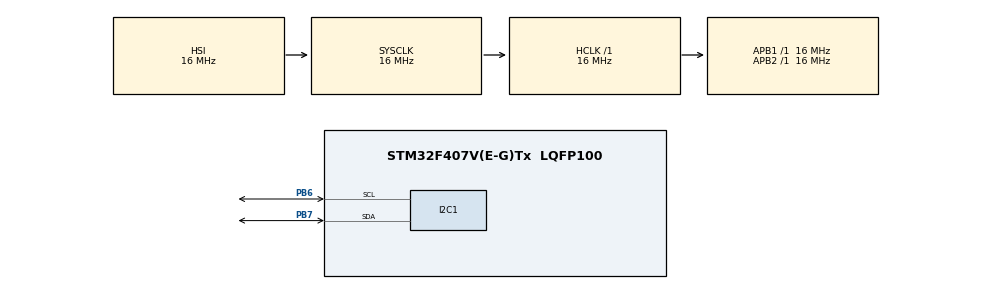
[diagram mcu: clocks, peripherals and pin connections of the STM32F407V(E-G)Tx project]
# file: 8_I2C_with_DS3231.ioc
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I2C1.I2C_Mode=I2C_Fast
Mcu.Family=STM32F4
Mcu.Name=STM32F407V(E-G)Tx
Mcu.Package=LQFP100
NVIC.PriorityGroup=NVIC_PRIORITYGROUP_4
PB6.Mode=I2C
PB6.Signal=I2C1_SCL
PB7.Mode=I2C
PB7.Signal=I2C1_SDA
ProjectManager.HeapSize=0x200
ProjectManager.StackSize=0x400
ProjectManager.TargetToolchain=STM32CubeIDE
RCC.AHBFreq_Value=16000000
RCC.APB1Freq_Value=16000000
RCC.APB2Freq_Value=16000000
RCC.CortexFreq_Value=16000000
RCC.HSE_VALUE=25000000
RCC.HSI_VALUE=16000000
RCC.LSE_VALUE=32768
RCC.SYSCLKFreq_VALUE=16000000
RCC.VCOOutputFreq_Value=192000000
board=custom

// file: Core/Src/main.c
/* USER CODE BEGIN Header */
/**
  ******************************************************************************
  * @file           : main.c
  * @brief          : Main program body
  ******************************************************************************
  * @attention
  *
  * Copyright (c) 2026 STMicroelectronics.
  * All rights reserved.
  *
  * This software is licensed under terms that can be found in the LICENSE file
  * in the root directory of this software component.
  * If no LICENSE file comes with this software, it is provided AS-IS.
  *
  ******************************************************************************
  */
/* USER CODE END Header */
#include "main.h"

/* USER CODE BEGIN PD */
#define DS3231_WRITE_ADDRESS 0xD0   // Decimal 208 is WRITE address for DS3231. so Hexadecimal is D0.
#define DS3231_READ_ADDRESS 0xD1    // Decimal 209 is READ address for DS3231. so, Hexadecimal is D1.
/* USER CODE END PD */

I2C_HandleTypeDef hi2c1;

/* USER CODE BEGIN PV */
typedef struct
{
	uint8_t second;
	uint8_t minute;
	uint8_t hour;
	uint8_t dayOfWeek;
	uint8_t dayOfMonth;
	uint8_t month;
	uint8_t year;
} DS3231_Time_t;

DS3231_Time_t	ds3231Time;

/* USER CODE END PV */

void SystemClock_Config(void);
static void MX_GPIO_Init(void);
static void MX_I2C1_Init(void);

/* USER CODE BEGIN 0 */
uint8_t DEC_TO_BCD(uint8_t value)
{
	return ((value / 10 * 16) + (value % 10));	// Basamaklara ayır, onlar basamağını sola 4 bit kaydır
												// ve bir ler basamağını aynen ekle.
}

uint8_t BCD_TO_DEC(uint8_t value)
{
	return ((value / 16 * 10) + (value % 16));  //  value/16 üst 4 biti alır, value%16 alt 4 biti alır
}

void DS3231_Set_Time(uint8_t second, uint8_t minute, uint8_t hour, uint8_t dayOfWeek, uint8_t dayOfMonth,
		             uint8_t month, uint8_t year)
{
	uint8_t time_data[7] = {0};     // ilk değeri sıfır olsun.

	time_data[0] = DEC_TO_BCD(second);
	time_data[1] = DEC_TO_BCD(minute);
	time_data[2] = DEC_TO_BCD(hour);
	time_data[3] = DEC_TO_BCD(dayOfWeek);
	time_data[4] = DEC_TO_BCD(dayOfMonth);
	time_data[5] = DEC_TO_BCD(month);
	time_data[6] = DEC_TO_BCD(year);

	HAL_I2C_Mem_Write(&hi2c1, DS3231_WRITE_ADDRESS, 0x00, 1, time_data, 7, HAL_MAX_DELAY);

}

DS3231_Time_t DS3231_Get_Time(void)
{
	DS3231_Time_t dsTime = {0};
	uint8_t receiveData[7] = {0};
	if(HAL_I2C_Mem_Read(&hi2c1, DS3231_READ_ADDRESS, 0x00, 1, receiveData, 7, HAL_MAX_DELAY) == HAL_OK)
	{
		dsTime.second = BCD_TO_DC(receiveData[0]);
		dsTime.minute = BCD_TO_DC(receiveData[1]);
		dsTime.hour = BCD_TO_DC(receiveData[2]);
		dsTime.dayOfWeek = BCD_TO_DC(receiveData[3]);
		dsTime.dayOfMonth = BCD_TO_DC(receiveData[4]);
		dsTime.month = BCD_TO_DC(receiveData[5]);
		dsTime.year = BCD_TO_DC(receiveData[6]) + 2000;
	}

	return dsTime;
}
/* USER CODE END 0 */

int main(void)
{

  /* MCU Configuration--------------------------------------------------------*/

  /* Reset of all peripherals, Initializes the Flash interface and the Systick. */
  HAL_Init();

  /* Configure the system clock */
  SystemClock_Config();

  /* Initialize all configured peripherals */
  MX_GPIO_Init();
  MX_I2C1_Init();
  /* USER CODE BEGIN 2 */
  DS3231_Set_Time(0, 0, 12, 3, 13, 6, 35);	// 12:00:00 _ 13/06/2035 _ Haftanın 3.günü.
  /* USER CODE END 2 */

  /* Infinite loop */
  while (1)
  {

    /* USER CODE BEGIN 3 */
	ds3231Time = DS3231_Get_Time();
	HAL_Delay(3000);					// 3sn de bir değer oku.

  }
  /* USER CODE END 3 */
}

void SystemClock_Config(void)
{
  RCC_OscInitTypeDef RCC_OscInitStruct = {0};
  RCC_ClkInitTypeDef RCC_ClkInitStruct = {0};

  /** Configure the main internal regulator output voltage
  */
  __HAL_RCC_PWR_CLK_ENABLE();
  __HAL_PWR_VOLTAGESCALING_CONFIG(PWR_REGULATOR_VOLTAGE_SCALE1);

  /** Initializes the RCC Oscillators according to the specified parameters
  * in the RCC_OscInitTypeDef structure.
  */
  RCC_OscInitStruct.OscillatorType = RCC_OSCILLATORTYPE_HSI;
  RCC_OscInitStruct.HSIState = RCC_HSI_ON;
  RCC_OscInitStruct.HSICalibrationValue = RCC_HSICALIBRATION_DEFAULT;
  RCC_OscInitStruct.PLL.PLLState = RCC_PLL_NONE;
  if (HAL_RCC_OscConfig(&RCC_OscInitStruct) != HAL_OK)
  {
    Error_Handler();
  }

  /** Initializes the CPU, AHB and APB buses clocks
  */
  RCC_ClkInitStruct.ClockType = RCC_CLOCKTYPE_HCLK|RCC_CLOCKTYPE_SYSCLK
                              |RCC_CLOCKTYPE_PCLK1|RCC_CLOCKTYPE_PCLK2;
  RCC_ClkInitStruct.SYSCLKSource = RCC_SYSCLKSOURCE_HSI;
  RCC_ClkInitStruct.AHBCLKDivider = RCC_SYSCLK_DIV1;
  RCC_ClkInitStruct.APB1CLKDivider = RCC_HCLK_DIV1;
  RCC_ClkInitStruct.APB2CLKDivider = RCC_HCLK_DIV1;

  if (HAL_RCC_ClockConfig(&RCC_ClkInitStruct, FLASH_LATENCY_0) != HAL_OK)
  {
    Error_Handler();
  }
}

static void MX_I2C1_Init(void)
{

  hi2c1.Instance = I2C1;
  hi2c1.Init.ClockSpeed = 400000;
  hi2c1.Init.DutyCycle = I2C_DUTYCYCLE_2;
  hi2c1.Init.OwnAddress1 = 0;
  hi2c1.Init.AddressingMode = I2C_ADDRESSINGMODE_7BIT;
  hi2c1.Init.DualAddressMode = I2C_DUALADDRESS_DISABLE;
  hi2c1.Init.OwnAddress2 = 0;
  hi2c1.Init.GeneralCallMode = I2C_GENERALCALL_DISABLE;
  hi2c1.Init.NoStretchMode = I2C_NOSTRETCH_DISABLE;
  if (HAL_I2C_Init(&hi2c1) != HAL_OK)
  {
    Error_Handler();
  }

}

static void MX_GPIO_Init(void)
{

  /* GPIO Ports Clock Enable */
  __HAL_RCC_GPIOB_CLK_ENABLE();

}

void Error_Handler(void)
{
  __disable_irq();
  while (1)
  {
  }
}
